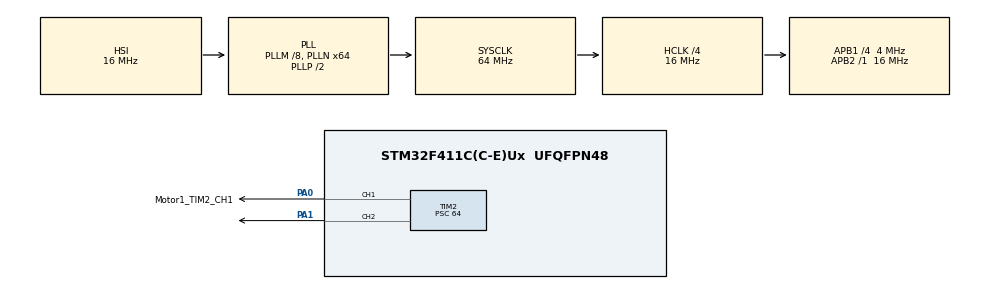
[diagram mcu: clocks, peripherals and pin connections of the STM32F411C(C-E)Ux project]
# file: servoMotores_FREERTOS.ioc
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FREERTOS.Tasks01=Motor1,24,128,StartGripper,Default,NULL,Dynamic,NULL,NULL;Motor2,24,128,StartArt,Default,NULL,Dynamic,NULL,NULL;stopMotors,24,128,StopMotorMov,Default,NULL,Dynamic,NULL,NULL
FREERTOS.configUSE_NEWLIB_REENTRANT=1
Mcu.Family=STM32F4
Mcu.Name=STM32F411C(C-E)Ux
Mcu.Package=UFQFPN48
NVIC.PriorityGroup=NVIC_PRIORITYGROUP_4
NVIC.TIM2_IRQn=true\:5\:0\:false\:false\:true\:true\:true\:true\:true
NVIC.TIM3_IRQn=true\:15\:0\:false\:false\:true\:false\:false\:true\:true
NVIC.TimeBase=TIM3_IRQn
NVIC.TimeBaseIP=TIM3
PA0-WKUP.GPIO_Label=Motor1_TIM2_CH1
PA0-WKUP.Signal=S_TIM2_CH1_ETR
PA1.Signal=S_TIM2_CH2
PA13.Mode=Serial_Wire
PA13.Signal=SYS_JTMS-SWDIO
PA14.Mode=Serial_Wire
PA14.Signal=SYS_JTCK-SWCLK
PC14-OSC32_IN.Mode=LSE-External-Oscillator
PC14-OSC32_IN.Signal=RCC_OSC32_IN
PC15-OSC32_OUT.Mode=LSE-External-Oscillator
PC15-OSC32_OUT.Signal=RCC_OSC32_OUT
PH0\ -\ OSC_IN.Mode=HSE-External-Oscillator
PH0\ -\ OSC_IN.Signal=RCC_OSC_IN
PH1\ -\ OSC_OUT.Mode=HSE-External-Oscillator
PH1\ -\ OSC_OUT.Signal=RCC_OSC_OUT
ProjectManager.HeapSize=0x200
ProjectManager.StackSize=0x400
ProjectManager.TargetToolchain=STM32CubeIDE
RCC.48MHZClocksFreq_Value=32000000
RCC.AHBCLKDivider=RCC_SYSCLK_DIV4
RCC.AHBFreq_Value=16000000
RCC.APB1CLKDivider=RCC_HCLK_DIV4
RCC.APB1Freq_Value=4000000
RCC.APB1TimFreq_Value=8000000
RCC.APB2Freq_Value=16000000
RCC.APB2TimFreq_Value=16000000
RCC.CortexFreq_Value=16000000
RCC.HCLKFreq_Value=16000000
RCC.HSE_VALUE=25000000
RCC.HSI_VALUE=16000000
RCC.PLLM=8
RCC.PLLN=64
RCC.SYSCLKFreq_VALUE=64000000
RCC.SYSCLKSource=RCC_SYSCLKSOURCE_PLLCLK
RCC.VCOOutputFreq_Value=128000000
SH.S_TIM2_CH1_ETR.0=TIM2_CH1,PWM Generation1 CH1
SH.S_TIM2_CH2.0=TIM2_CH2,PWM Generation2 CH2
TIM2.Channel-PWM\ Generation1\ CH1=TIM_CHANNEL_1
TIM2.Channel-PWM\ Generation2\ CH2=TIM_CHANNEL_2
TIM2.Period=2499
TIM2.Prescaler=64
VP_FREERTOS_VS_CMSIS_V2.Mode=CMSIS_V2
VP_SYS_VS_tim3.Mode=TIM3
VP_TIM2_VS_ClockSourceINT.Mode=Internal
board=custom

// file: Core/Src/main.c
/* USER CODE BEGIN Header */
/**
  ******************************************************************************
  * @file           : main.c
  * @brief          : Main program body
  ******************************************************************************
  * @attention
  *
  * Copyright (c) 2023 STMicroelectronics.
  * All rights reserved.
  *
  * This software is licensed under terms that can be found in the LICENSE file
  * in the root directory of this software component.
  * If no LICENSE file comes with this software, it is provided AS-IS.
  *
  ******************************************************************************
  */
/* USER CODE END Header */
#include "main.h"
#include "cmsis_os.h"

TIM_HandleTypeDef htim2;

/* Definitions for Motor1 */
osThreadId_t Motor1Handle;
const osThreadAttr_t Motor1_attributes = {
  .name = "Motor1",
  .stack_size = 128 * 4,
  .priority = (osPriority_t) osPriorityNormal,
};
/* Definitions for Motor2 */
osThreadId_t Motor2Handle;
const osThreadAttr_t Motor2_attributes = {
  .name = "Motor2",
  .stack_size = 128 * 4,
  .priority = (osPriority_t) osPriorityNormal,
};
/* Definitions for stopMotors */
osThreadId_t stopMotorsHandle;
const osThreadAttr_t stopMotors_attributes = {
  .name = "stopMotors",
  .stack_size = 128 * 4,
  .priority = (osPriority_t) osPriorityNormal,
};
/* USER CODE BEGIN PV */
int gripper = 0, art = 0;
/* USER CODE END PV */

void SystemClock_Config(void);
static void MX_GPIO_Init(void);
static void MX_TIM2_Init(void);
void StartGripper(void *argument);
void StartArt(void *argument);
void StopMotorMov(void *argument);

int main(void)
{

  /* MCU Configuration--------------------------------------------------------*/

  /* Reset of all peripherals, Initializes the Flash interface and the Systick. */
  HAL_Init();

  /* Configure the system clock */
  SystemClock_Config();

  /* Initialize all configured peripherals */
  MX_GPIO_Init();
  MX_TIM2_Init();
  /* USER CODE BEGIN 2 */

  HAL_TIM_PWM_Start(&htim2,TIM_CHANNEL_1);
  HAL_TIM_PWM_Start(&htim2,TIM_CHANNEL_2);
  /* USER CODE END 2 */

  /* Init scheduler */
  osKernelInitialize();

  /* Create the thread(s) */
  /* creation of Motor1 */
  Motor1Handle = osThreadNew(StartGripper, NULL, &Motor1_attributes);

  /* creation of Motor2 */
  Motor2Handle = osThreadNew(StartArt, NULL, &Motor2_attributes);

  /* creation of stopMotors */
  stopMotorsHandle = osThreadNew(StopMotorMov, NULL, &stopMotors_attributes);

  /* Start scheduler */
  osKernelStart();
  /* We should never get here as control is now taken by the scheduler */
  /* Infinite loop */
  while (1)
  {

  }
}

void SystemClock_Config(void)
{
  RCC_OscInitTypeDef RCC_OscInitStruct = {0};
  RCC_ClkInitTypeDef RCC_ClkInitStruct = {0};

  /** Configure the main internal regulator output voltage
  */
  __HAL_RCC_PWR_CLK_ENABLE();
  __HAL_PWR_VOLTAGESCALING_CONFIG(PWR_REGULATOR_VOLTAGE_SCALE1);

  /** Initializes the RCC Oscillators according to the specified parameters
  * in the RCC_OscInitTypeDef structure.
  */
  RCC_OscInitStruct.OscillatorType = RCC_OSCILLATORTYPE_HSI;
  RCC_OscInitStruct.HSIState = RCC_HSI_ON;
  RCC_OscInitStruct.HSICalibrationValue = RCC_HSICALIBRATION_DEFAULT;
  RCC_OscInitStruct.PLL.PLLState = RCC_PLL_ON;
  RCC_OscInitStruct.PLL.PLLSource = RCC_PLLSOURCE_HSI;
  RCC_OscInitStruct.PLL.PLLM = 8;
  RCC_OscInitStruct.PLL.PLLN = 64;
  RCC_OscInitStruct.PLL.PLLP = RCC_PLLP_DIV2;
  RCC_OscInitStruct.PLL.PLLQ = 4;
  if (HAL_RCC_OscConfig(&RCC_OscInitStruct) != HAL_OK)
  {
    Error_Handler();
  }

  /** Initializes the CPU, AHB and APB buses clocks
  */
  RCC_ClkInitStruct.ClockType = RCC_CLOCKTYPE_HCLK|RCC_CLOCKTYPE_SYSCLK
                              |RCC_CLOCKTYPE_PCLK1|RCC_CLOCKTYPE_PCLK2;
  RCC_ClkInitStruct.SYSCLKSource = RCC_SYSCLKSOURCE_PLLCLK;
  RCC_ClkInitStruct.AHBCLKDivider = RCC_SYSCLK_DIV4;
  RCC_ClkInitStruct.APB1CLKDivider = RCC_HCLK_DIV4;
  RCC_ClkInitStruct.APB2CLKDivider = RCC_HCLK_DIV1;

  if (HAL_RCC_ClockConfig(&RCC_ClkInitStruct, FLASH_LATENCY_0) != HAL_OK)
  {
    Error_Handler();
  }
}

static void MX_TIM2_Init(void)
{

  TIM_ClockConfigTypeDef sClockSourceConfig = {0};
  TIM_MasterConfigTypeDef sMasterConfig = {0};
  TIM_OC_InitTypeDef sConfigOC = {0};

  htim2.Instance = TIM2;
  htim2.Init.Prescaler = 64;
  htim2.Init.CounterMode = TIM_COUNTERMODE_UP;
  htim2.Init.Period = 2499;
  htim2.Init.ClockDivision = TIM_CLOCKDIVISION_DIV1;
  htim2.Init.AutoReloadPreload = TIM_AUTORELOAD_PRELOAD_DISABLE;
  if (HAL_TIM_Base_Init(&htim2) != HAL_OK)
  {
    Error_Handler();
  }
  sClockSourceConfig.ClockSource = TIM_CLOCKSOURCE_INTERNAL;
  if (HAL_TIM_ConfigClockSource(&htim2, &sClockSourceConfig) != HAL_OK)
  {
    Error_Handler();
  }
  if (HAL_TIM_PWM_Init(&htim2) != HAL_OK)
  {
    Error_Handler();
  }
  sMasterConfig.MasterOutputTrigger = TIM_TRGO_RESET;
  sMasterConfig.MasterSlaveMode = TIM_MASTERSLAVEMODE_DISABLE;
  if (HAL_TIMEx_MasterConfigSynchronization(&htim2, &sMasterConfig) != HAL_OK)
  {
    Error_Handler();
  }
  sConfigOC.OCMode = TIM_OCMODE_PWM1;
  sConfigOC.Pulse = 0;
  sConfigOC.OCPolarity = TIM_OCPOLARITY_HIGH;
  sConfigOC.OCFastMode = TIM_OCFAST_DISABLE;
  if (HAL_TIM_PWM_ConfigChannel(&htim2, &sConfigOC, TIM_CHANNEL_1) != HAL_OK)
  {
    Error_Handler();
  }
  if (HAL_TIM_PWM_ConfigChannel(&htim2, &sConfigOC, TIM_CHANNEL_2) != HAL_OK)
  {
    Error_Handler();
  }
  HAL_TIM_MspPostInit(&htim2);

}

static void MX_GPIO_Init(void)
{

  /* GPIO Ports Clock Enable */
  __HAL_RCC_GPIOC_CLK_ENABLE();
  __HAL_RCC_GPIOH_CLK_ENABLE();
  __HAL_RCC_GPIOA_CLK_ENABLE();

}

void StartGripper(void *argument)
{
  /* USER CODE BEGIN 5 */
  /* Infinite loop */
  for(;;)
  {
	  TIM2->CCR1 = 131;
	  gripper = 131;

      osDelay(100);
  }
  /* USER CODE END 5 */
}

void StartArt(void *argument)
{
  /* USER CODE BEGIN StartArt */
  /* Infinite loop */
  for(;;)
  {
	  TIM2->CCR2 = 83;
	  art = 83;

	  osDelay(100);
  }
  /* USER CODE END StartArt */
}

void StopMotorMov(void *argument)
{
  for(;;)
  {
    osDelay(1);
  }
}

void HAL_TIM_PeriodElapsedCallback(TIM_HandleTypeDef *htim)
{
  if (htim->Instance == TIM3) {
    HAL_IncTick();
  }
}

void Error_Handler(void)
{
  __disable_irq();
  while (1)
  {
  }
}
